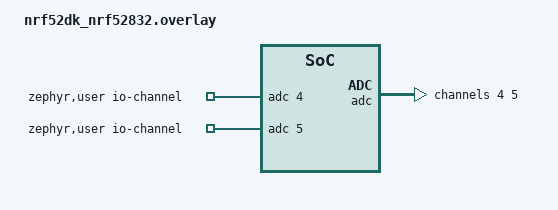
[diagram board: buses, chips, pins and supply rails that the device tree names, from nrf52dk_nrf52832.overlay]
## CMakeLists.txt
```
cmake_minimum_required(VERSION 3.20.0)
find_package(Zephyr REQUIRED HINTS $ENV{ZEPHYR_BASE})

project(SensorTest)

target_include_directories(app PRIVATE include)

target_sources(app PRIVATE 

"include/gpio/adc.hpp"
"include/gpio/gpio.hpp"

"src/gpio/adc.cpp"
"src/gpio/gpio.cpp"

"src/main.cpp"

)
```

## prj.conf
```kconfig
# enable ADC
CONFIG_ADC=y

# configure logging via rtt
CONFIG_LOG=y
CONFIG_LOG_BACKEND_RTT=y
CONFIG_LOG_MODE_DEFERRED=y
CONFIG_LOG_PRINTK=y
CONFIG_USE_SEGGER_RTT=y
```

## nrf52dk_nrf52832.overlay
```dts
/ {
    zephyr,user {
        io-channels = <&adc 4>, <&adc 5>;
    };
};

&adc {
    status = "okay";  // Ensure the ADC device is enabled
    #address-cells = <1>;
    #size-cells = <0>;

    channel@4 {
        reg = <4>;
        zephyr,gain = "ADC_GAIN_1_6";
        zephyr,reference = "ADC_REF_INTERNAL";
        zephyr,acquisition-time = <ADC_ACQ_TIME_DEFAULT>;
        zephyr,input-positive = <NRF_SAADC_AIN4>; // Updated for P0.28
        zephyr,resolution = <12>;
    };
    channel@5 {
        reg = <5>;
        zephyr,gain = "ADC_GAIN_1_6";
        zephyr,reference = "ADC_REF_INTERNAL";
        zephyr,acquisition-time = <ADC_ACQ_TIME_DEFAULT>;
        zephyr,input-positive = <NRF_SAADC_AIN5>;  // Updated for P0.29
        zephyr,resolution = <12>;
    };
};
```

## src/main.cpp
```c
/*
 * Copyright (c) 2016 Intel Corporation
 *
 * SPDX-License-Identifier: Apache-2.0
 */

#include <stdio.h>
#include <zephyr/kernel.h>
#include <zephyr/drivers/gpio.h>
#include <zephyr/drivers/adc.h>
#include <zephyr/device.h>
#include <zephyr/devicetree.h>
#include <zephyr/drivers/adc.h>
#include <zephyr/kernel.h>
#include <zephyr/sys/printk.h>
#include <zephyr/sys/util.h>
#include <zephyr/logging/log.h>
/* 1000 msec = 1 sec */
#define SLEEP_TIME_MS 1000

#include "gpio/adc.hpp"
#include "gpio/gpio.hpp"

int32_t voltage = 0;

LOG_MODULE_REGISTER(main);

int main(void)
{
    gpio::adc::setup();
    gpio::gpio_result result = gpio::init();

    while (1)
    {
        gpio::adc::read_channel(0, voltage);
        LOG_INF("ADC reading [%u]: %u  ", 4, voltage);
        gpio::adc::read_channel(1, voltage);
        LOG_INF("ADC reading [%u]: %u", 5, voltage);

        k_sleep(K_MSEC(SLEEP_TIME_MS));
    }
    return 0;
}
```
